# ATmega16U2 device description
Architecture: AVR8; Family: megaAVR
Registers are 8-bit, access not given, no defined reset value unless marked. A register's access mark holds for its fields unless they carry their own. Offsets are from the block's base; [hi:lo] are bit positions; {n}, {i} and the like mark numbered series.

## CPU — CPU Registers
Instances: CPU 0x00
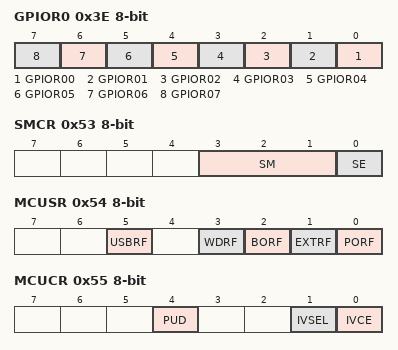
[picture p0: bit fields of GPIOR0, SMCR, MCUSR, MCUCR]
0x3E GPIOR0 — General Purpose IO Register 0
  [n] GPIOR{n:02} (n=0..7) — General Purpose IO Register 0 bit {n}
0x4A GPIOR1 — General Purpose IO Register 1
  [7:0] GPIOR (bit 10 of the value upward) — General Purpose IO Register 1 bis
0x4B GPIOR2 — General Purpose IO Register 2
  [7:0] GPIOR (bit 20 of the value upward) — General Purpose IO Register 2 bis
0x51 DWDR — debugWire communication register
0x53 SMCR — Sleep Mode Control Register
  [3:1] SM — Sleep Mode Select bits
    0=IDLE; 2=PDOWN (Power Down); 3=PSAVE (Power Save); 6=STDBY (Standby); 7=ESTDBY (Extended Standby)
  [0] SE — Sleep Enable
0x54 MCUSR — MCU Status Register
  [5] USBRF — USB reset flag
  [3] WDRF — Watchdog Reset Flag
  [2] BORF — Brown-out Reset Flag
  [1] EXTRF — External Reset Flag
  [0] PORF — Power-on reset flag
0x55 MCUCR — MCU Control Register
  [4] PUD — Pull-up disable
  [1] IVSEL — Interrupt Vector Select
  [0] IVCE — Interrupt Vector Change Enable
0x5C EIND bits used 0 — Extended Indirect Register
0x5D SP 16-bit — Stack Pointer
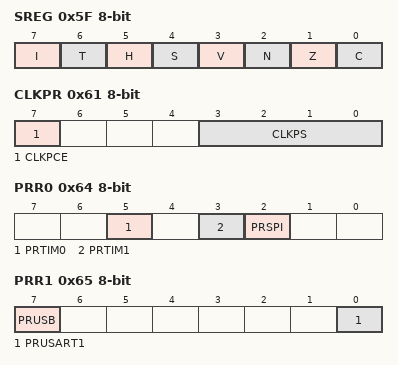
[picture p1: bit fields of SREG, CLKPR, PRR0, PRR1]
0x5F SREG — Status Register
  [7] I — Global Interrupt Enable
  [6] T — Bit Copy Storage
  [5] H — Half Carry Flag
  [4] S — Sign Bit
  [3] V — Two's Complement Overflow Flag
  [2] N — Negative Flag
  [1] Z — Zero Flag
  [0] C — Carry Flag
0x61 CLKPR
  [7] CLKPCE, [3:0] CLKPS
0x64 PRR0 — Power Reduction Register0
  [5] PRTIM0 — Power Reduction Timer/Counter0
  [3] PRTIM1 — Power Reduction Timer/Counter1
  [2] PRSPI — Power Reduction Serial Peripheral Interface
0x65 PRR1 — Power Reduction Register1
  [7] PRUSB — Power Reduction USB
  [0] PRUSART1 — Power Reduction USART1
0x66 OSCCAL — Oscillator Calibration Value
  [7:0] OSCCAL — Oscillator Calibration
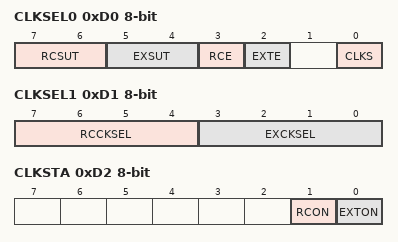
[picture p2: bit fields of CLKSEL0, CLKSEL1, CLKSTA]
0xD0 CLKSEL0
  [7:6] RCSUT, [5:4] EXSUT, [3] RCE, [2] EXTE, [0] CLKS
0xD1 CLKSEL1
  [7:4] RCCKSEL, [3:0] EXCKSEL
0xD2 CLKSTA
  [1] RCON, [0] EXTON
Value list OSCCAL_VALUE_ADDRESSES: 0=8_0_MHz

## EXINT — External Interrupts
Instances: EXINT 0x00
0x3B PCIFR — Pin Change Interrupt Flag Register
  [1:0] PCIF — Pin Change Interrupt Flags
0x3C EIFR — External Interrupt Flag Register
  [7:0] INTF — External Interrupt Flags
0x3D EIMSK — External Interrupt Mask Register
  [7:0] INT — External Interrupt Request 7 Enable
0x68 PCICR — Pin Change Interrupt Control Register
  [1:0] PCIE — Pin Change Interrupt Enables
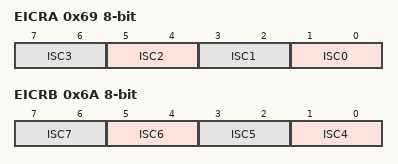
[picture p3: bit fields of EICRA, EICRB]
0x69 EICRA — External Interrupt Control Register A
  [2n+1:2n] ISC{n} (n=0..3) — External Interrupt Sense Control Bit
0x6A EICRB — External Interrupt Control Register B
  [2n-7:2n-8] ISC{n} (n=4..7) — External Interrupt 7-4 Sense Control Bit
0x6B PCMSK0 — Pin Change Mask Register 0
  [7:0] PCINT — Pin Change Enable Masks
0x6C PCMSK1 — Pin Change Mask Register 1
  [4:0] PCINT (bit 8 of the value upward)

## USART1 — USART
Instances: USART1 0x00
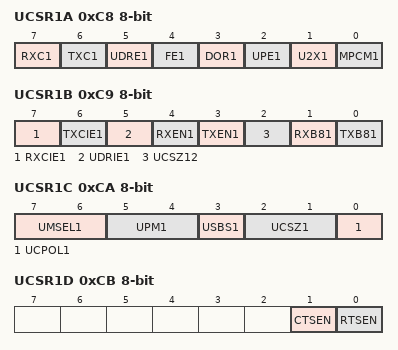
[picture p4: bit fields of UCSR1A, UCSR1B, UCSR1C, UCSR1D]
0xC8 UCSR1A — USART Control and Status Register A
  [7] RXC1 — USART Receive Complete
  [6] TXC1 — USART Transmit Complete
  [5] UDRE1 — USART Data Register Empty
  [4] FE1 — Framing Error
  [3] DOR1 — Data overRun
  [2] UPE1 — Parity Error
  [1] U2X1 — Double the USART transmission speed
  [0] MPCM1 — Multi-processor Communication Mode
0xC9 UCSR1B — USART Control and Status Register B
  [7] RXCIE1 — RX Complete Interrupt Enable
  [6] TXCIE1 — TX Complete Interrupt Enable
  [5] UDRIE1 — USART Data register Empty Interrupt Enable
  [4] RXEN1 — Receiver Enable
  [3] TXEN1 — Transmitter Enable
  [2] UCSZ12 — Character Size
  [1] RXB81 — Receive Data Bit 8
  [0] TXB81 — Transmit Data Bit 8
0xCA UCSR1C — USART Control and Status Register C
  [7:6] UMSEL1 — USART Mode Select
  [5:4] UPM1 — Parity Mode Bits
  [3] USBS1 — Stop Bit Select
  [2:1] UCSZ1 — Character Size
  [0] UCPOL1 — Clock Polarity
0xCB UCSR1D — USART Control and Status Register D
  [1] CTSEN — CTS Enable
  [0] RTSEN — RTS Enable
0xCC UBRR1 16-bit — USART Baud Rate Register Bytes
  [11:0] UBRR1 — USART Baud Rate bits
0xCE UDR1 — USART I/O Data Register
  [7:0] UDR1 — USART I/O Data bits

## WDT — Watchdog Timer
Instances: WDT 0x00
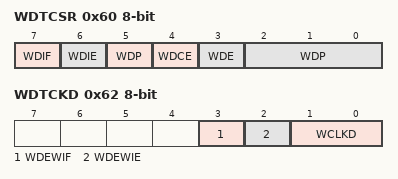
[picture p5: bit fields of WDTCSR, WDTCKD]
0x60 WDTCSR — Watchdog Timer Control Register
  [7] WDIF — Watchdog Timeout Interrupt Flag
  [6] WDIE — Watchdog Timeout Interrupt Enable
  [4] WDCE — Watchdog Change Enable
  [3] WDE — Watch Dog Enable
  [5,2:0] WDP — Watchdog Timer Prescaler Bits
0x62 WDTCKD — Watchdog Timer Clock Divider
  [3] WDEWIF — Watchdog Early Warning Interrupt Flag
  [2] WDEWIE — Watchdog Early Warning Interrupt Enable
  [1:0] WCLKD — Watchdog Timer Clock Dividers

## AC — Analog Comparator
Instances: AC 0x00
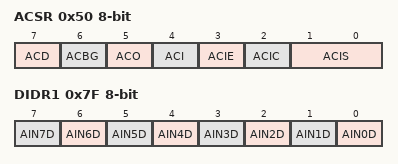
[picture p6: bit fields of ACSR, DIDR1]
0x50 ACSR — Analog Comparator Control And Status Register
  [7] ACD — Analog Comparator Disable
  [6] ACBG — Analog Comparator Bandgap Select
  [5] ACO — Analog Compare Output
  [4] ACI — Analog Comparator Interrupt Flag
  [3] ACIE — Analog Comparator Interrupt Enable
  [2] ACIC — Analog Comparator Input Capture Enable
  [1:0] ACIS — Analog Comparator Interrupt Mode Select bits
    0=INTERRUPT_ON_TOGGLE; 2=INTERRUPT_ON_FALLING_EDGE; 3=INTERRUPT_ON_RISING_EDGE
0x7D ACMUX — Analog Comparator Input Multiplexer
  [2:0] CMUX — Analog Comparator Selection Bits
    {v}=AIN{v+1} (v=0..5)
0x7F DIDR1
  [n] AIN{n}D (n=0..7) — AIN{n} Digital Input Disable
